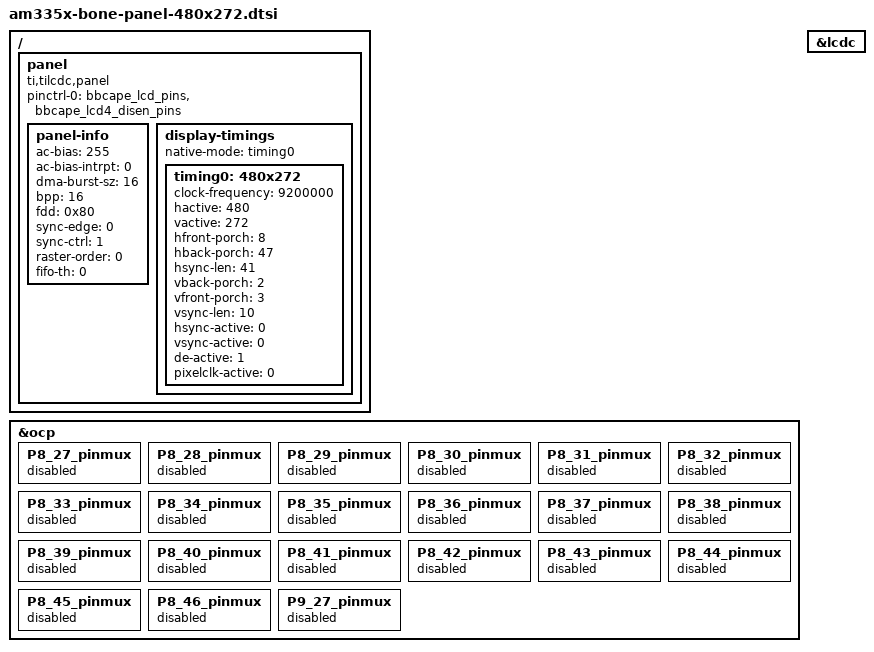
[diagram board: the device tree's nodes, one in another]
/*
 * Copyright (C) 2012 Texas Instruments Incorporated - http://www.ti.com/
 *
 * This program is free software; you can redistribute it and/or modify
 * it under the terms of the GNU General Public License version 2 as
 * published by the Free Software Foundation.
 */

&ocp {
	/* hdmi */
	P8_27_pinmux {
		status = "disabled";
	};
	P8_28_pinmux {
		status = "disabled";
	};
	P8_29_pinmux {
		status = "disabled";
	};
	P8_30_pinmux {
		status = "disabled";
	};
	P8_31_pinmux {
		status = "disabled";
	};
	P8_32_pinmux {
		status = "disabled";
	};
	P8_33_pinmux {
		status = "disabled";
	};
	P8_34_pinmux {
		status = "disabled";
	};
	P8_35_pinmux {
		status = "disabled";
	};
	P8_36_pinmux {
		status = "disabled";
	};
	P8_37_pinmux {
		status = "disabled";
	};
	P8_38_pinmux {
		status = "disabled";
	};
	P8_39_pinmux {
		status = "disabled";
	};
	P8_40_pinmux {
		status = "disabled";
	};
	P8_41_pinmux {
		status = "disabled";
	};
	P8_42_pinmux {
		status = "disabled";
	};
	P8_43_pinmux {
		status = "disabled";
	};
	P8_44_pinmux {
		status = "disabled";
	};
	P8_45_pinmux {
		status = "disabled";
	};
	P8_46_pinmux {
		status = "disabled";
	};
	/* fixme: what are you? */
	P9_27_pinmux {
		status = "disabled";
	};
};

&lcdc {
	status = "okay";
};

/ {
	panel {
		status = "okay";
		compatible = "ti,tilcdc,panel";
		pinctrl-names = "default";
		pinctrl-0 = <&bbcape_lcd_pins &bbcape_lcd4_disen_pins>;
		panel-info {
			ac-bias           = <255>;
			ac-bias-intrpt    = <0>;
			dma-burst-sz      = <16>;
			bpp               = <16>;
			fdd               = <0x80>;
			sync-edge         = <0>;
			sync-ctrl         = <1>;
			raster-order      = <0>;
			fifo-th           = <0>;
		};
		display-timings {
			native-mode = <&timing0>;
			/* www.newhavendisplay.com/app_notes/OTA5180A.pdf */
			timing0: 480x272 {
				clock-frequency = <9200000>;
				hactive = <480>;
				vactive = <272>;
				hfront-porch = <8>;
				hback-porch = <47>;
				hsync-len = <41>;
				vback-porch = <2>;
				vfront-porch = <3>;
				vsync-len = <10>;
				hsync-active = <0>;
				vsync-active = <0>;
				de-active = <1>;
				pixelclk-active = <0>;
			};
		};
	};
};
